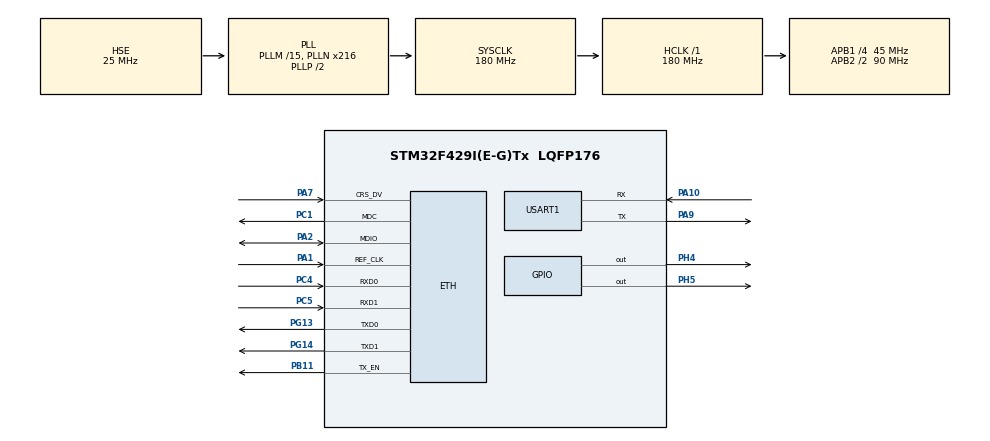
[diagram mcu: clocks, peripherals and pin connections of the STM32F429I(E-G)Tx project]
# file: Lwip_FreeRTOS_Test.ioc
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ETH.MediaInterface=HAL_ETH_RMII_MODE
FREERTOS.Tasks01=defaultTask,24,128,StartDefaultTask,Default,NULL,Dynamic,NULL,NULL
LWIP.BSP.number=1
LWIP.GATEWAY_ADDRESS=192.168.137.001
LWIP.IP_ADDRESS=192.168.137.100
LWIP.LWIP_DHCP=0
LWIP.LWIP_UDP=0
LWIP.NETMASK_ADDRESS=255.255.000.000
LWIP.Version=v2.1.2_Cube
LWIP0.BSP.STBoard=false
LWIP0.BSP.api=BSP_COMPONENT_DRIVER
LWIP0.BSP.component=LAN8742
LWIP0.BSP.instance=LAN8742
LWIP0.BSP.name=Driver_PHY
LWIP0.BSP.semaphore=S_LAN8742
LWIP0.BSP.solution=LAN8742
Mcu.Family=STM32F4
Mcu.Name=STM32F429I(E-G)Tx
Mcu.Package=LQFP176
NVIC.ETH_IRQn=true\:5\:0\:false\:false\:true\:true\:false\:true\:true
NVIC.PriorityGroup=NVIC_PRIORITYGROUP_4
NVIC.TIM8_TRG_COM_TIM14_IRQn=true\:15\:0\:false\:false\:true\:false\:false\:true\:true
NVIC.TimeBase=TIM8_TRG_COM_TIM14_IRQn
NVIC.TimeBaseIP=TIM14
PA1.Mode=RMII
PA1.Signal=ETH_REF_CLK
PA10.Mode=Asynchronous
PA10.Signal=USART1_RX
PA13.Mode=Serial_Wire
PA13.Signal=SYS_JTMS-SWDIO
PA14.Mode=Serial_Wire
PA14.Signal=SYS_JTCK-SWCLK
PA2.Mode=RMII
PA2.Signal=ETH_MDIO
PA7.Mode=RMII
PA7.Signal=ETH_CRS_DV
PA9.Mode=Asynchronous
PA9.Signal=USART1_TX
PB11.Mode=RMII
PB11.Signal=ETH_TX_EN
PC1.Mode=RMII
PC1.Signal=ETH_MDC
PC4.Mode=RMII
PC4.Signal=ETH_RXD0
PC5.Mode=RMII
PC5.Signal=ETH_RXD1
PG13.Mode=RMII
PG13.Signal=ETH_TXD0
PG14.Mode=RMII
PG14.Signal=ETH_TXD1
PH0/OSC_IN.Mode=HSE-External-Oscillator
PH0/OSC_IN.Signal=RCC_OSC_IN
PH1/OSC_OUT.Mode=HSE-External-Oscillator
PH1/OSC_OUT.Signal=RCC_OSC_OUT
PH4.GPIO_ModeDefaultOutputPP=GPIO_MODE_OUTPUT_PP
PH4.Signal=GPIO_Output
PH5.GPIO_ModeDefaultOutputPP=GPIO_MODE_OUTPUT_OD
PH5.GPIO_PuPd=GPIO_NOPULL
PH5.Signal=GPIO_Output
ProjectManager.HeapSize=0x200
ProjectManager.StackSize=0x2000
ProjectManager.TargetToolchain=Makefile
RCC.48MHZClocksFreq_Value=90000000
RCC.AHBFreq_Value=180000000
RCC.APB1CLKDivider=RCC_HCLK_DIV4
RCC.APB1Freq_Value=45000000
RCC.APB1TimFreq_Value=90000000
RCC.APB2CLKDivider=RCC_HCLK_DIV2
RCC.APB2Freq_Value=90000000
RCC.APB2TimFreq_Value=180000000
RCC.CortexFreq_Value=180000000
RCC.HCLKFreq_Value=180000000
RCC.HSE_VALUE=25000000
RCC.HSI_VALUE=16000000
RCC.LSE_VALUE=32768
RCC.PLLM=15
RCC.PLLN=216
RCC.PLLSourceVirtual=RCC_PLLSOURCE_HSE
RCC.SYSCLKFreq_VALUE=180000000
RCC.SYSCLKSource=RCC_SYSCLKSOURCE_PLLCLK
RCC.VCOOutputFreq_Value=360000000
USART1.VirtualMode=VM_ASYNC
VP_FREERTOS_VS_CMSIS_V2.Mode=CMSIS_V2
VP_LWIP_VS_Enabled.Mode=Enabled
VP_SYS_VS_tim14.Mode=TIM14
board=custom

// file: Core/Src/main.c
/* USER CODE BEGIN Header */
/**
  ******************************************************************************
  * @file           : main.c
  * @brief          : Main program body
  ******************************************************************************
  * @attention
  *
  * Copyright (c) 2025 STMicroelectronics.
  * All rights reserved.
  *
  * This software is licensed under terms that can be found in the LICENSE file
  * in the root directory of this software component.
  * If no LICENSE file comes with this software, it is provided AS-IS.
  *
  ******************************************************************************
  */
/* USER CODE END Header */
#include "main.h"
#include "cmsis_os.h"
#include "lwip.h"
#include "usart.h"
#include "gpio.h"

/* USER CODE BEGIN Includes */
#include "pcf8574.h"
/* USER CODE END Includes */

void SystemClock_Config(void);
void MX_FREERTOS_Init(void);

int main(void)
{

  /* MCU Configuration--------------------------------------------------------*/

  /* Reset of all peripherals, Initializes the Flash interface and the Systick. */
  HAL_Init();

  /* Configure the system clock */
  SystemClock_Config();

  /* Initialize all configured peripherals */
  MX_GPIO_Init();
  MX_USART1_UART_Init();
  /* USER CODE BEGIN 2 */
  PCF8574_Init();
  PCF8574_Write_Bit(7,1);
  HAL_Delay(100);
  PCF8574_Write_Bit(7,0);
  HAL_Delay(100);
  /* USER CODE END 2 */

  /* Init scheduler */
  osKernelInitialize();

  /* Call init function for freertos objects (in cmsis_os2.c) */
  MX_FREERTOS_Init();

  /* Start scheduler */
  osKernelStart();

  /* We should never get here as control is now taken by the scheduler */

  /* Infinite loop */
  while (1)
  {

  }
}

void SystemClock_Config(void)
{
  RCC_OscInitTypeDef RCC_OscInitStruct = {0};
  RCC_ClkInitTypeDef RCC_ClkInitStruct = {0};

  /** Configure the main internal regulator output voltage
  */
  __HAL_RCC_PWR_CLK_ENABLE();
  __HAL_PWR_VOLTAGESCALING_CONFIG(PWR_REGULATOR_VOLTAGE_SCALE1);

  /** Initializes the RCC Oscillators according to the specified parameters
  * in the RCC_OscInitTypeDef structure.
  */
  RCC_OscInitStruct.OscillatorType = RCC_OSCILLATORTYPE_HSE;
  RCC_OscInitStruct.HSEState = RCC_HSE_ON;
  RCC_OscInitStruct.PLL.PLLState = RCC_PLL_ON;
  RCC_OscInitStruct.PLL.PLLSource = RCC_PLLSOURCE_HSE;
  RCC_OscInitStruct.PLL.PLLM = 15;
  RCC_OscInitStruct.PLL.PLLN = 216;
  RCC_OscInitStruct.PLL.PLLP = RCC_PLLP_DIV2;
  RCC_OscInitStruct.PLL.PLLQ = 4;
  if (HAL_RCC_OscConfig(&RCC_OscInitStruct) != HAL_OK)
  {
    Error_Handler();
  }

  /** Activate the Over-Drive mode
  */
  if (HAL_PWREx_EnableOverDrive() != HAL_OK)
  {
    Error_Handler();
  }

  /** Initializes the CPU, AHB and APB buses clocks
  */
  RCC_ClkInitStruct.ClockType = RCC_CLOCKTYPE_HCLK|RCC_CLOCKTYPE_SYSCLK
                              |RCC_CLOCKTYPE_PCLK1|RCC_CLOCKTYPE_PCLK2;
  RCC_ClkInitStruct.SYSCLKSource = RCC_SYSCLKSOURCE_PLLCLK;
  RCC_ClkInitStruct.AHBCLKDivider = RCC_SYSCLK_DIV1;
  RCC_ClkInitStruct.APB1CLKDivider = RCC_HCLK_DIV4;
  RCC_ClkInitStruct.APB2CLKDivider = RCC_HCLK_DIV2;

  if (HAL_RCC_ClockConfig(&RCC_ClkInitStruct, FLASH_LATENCY_5) != HAL_OK)
  {
    Error_Handler();
  }
}

void HAL_TIM_PeriodElapsedCallback(TIM_HandleTypeDef *htim)
{
  if (htim->Instance == TIM14) {
    HAL_IncTick();
  }
}

void Error_Handler(void)
{
  __disable_irq();
  while (1)
  {
  }
}

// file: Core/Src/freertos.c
/* USER CODE BEGIN Header */
/**
  ******************************************************************************
  * File Name          : freertos.c
  * Description        : Code for freertos applications
  ******************************************************************************
  * @attention
  *
  * Copyright (c) 2025 STMicroelectronics.
  * All rights reserved.
  *
  * This software is licensed under terms that can be found in the LICENSE file
  * in the root directory of this software component.
  * If no LICENSE file comes with this software, it is provided AS-IS.
  *
  ******************************************************************************
  */
/* USER CODE END Header */

#include "FreeRTOS.h"
#include "task.h"
#include "main.h"
#include "cmsis_os.h"

/* Definitions for defaultTask */
osThreadId_t defaultTaskHandle;
const osThreadAttr_t defaultTask_attributes = {
  .name = "defaultTask",
  .stack_size = 512 * 4,
  .priority = (osPriority_t) osPriorityNormal,
};

void StartDefaultTask(void *argument);

extern void MX_LWIP_Init(void);
void MX_FREERTOS_Init(void); /* (MISRA C 2004 rule 8.1) */

void MX_FREERTOS_Init(void) {

  /* Create the thread(s) */
  /* creation of defaultTask */
  defaultTaskHandle = osThreadNew(StartDefaultTask, NULL, &defaultTask_attributes);

}

void StartDefaultTask(void *argument)
{
  /* init code for LWIP */
  MX_LWIP_Init();
  for(;;)
  {
    osDelay(1);
  }
}
